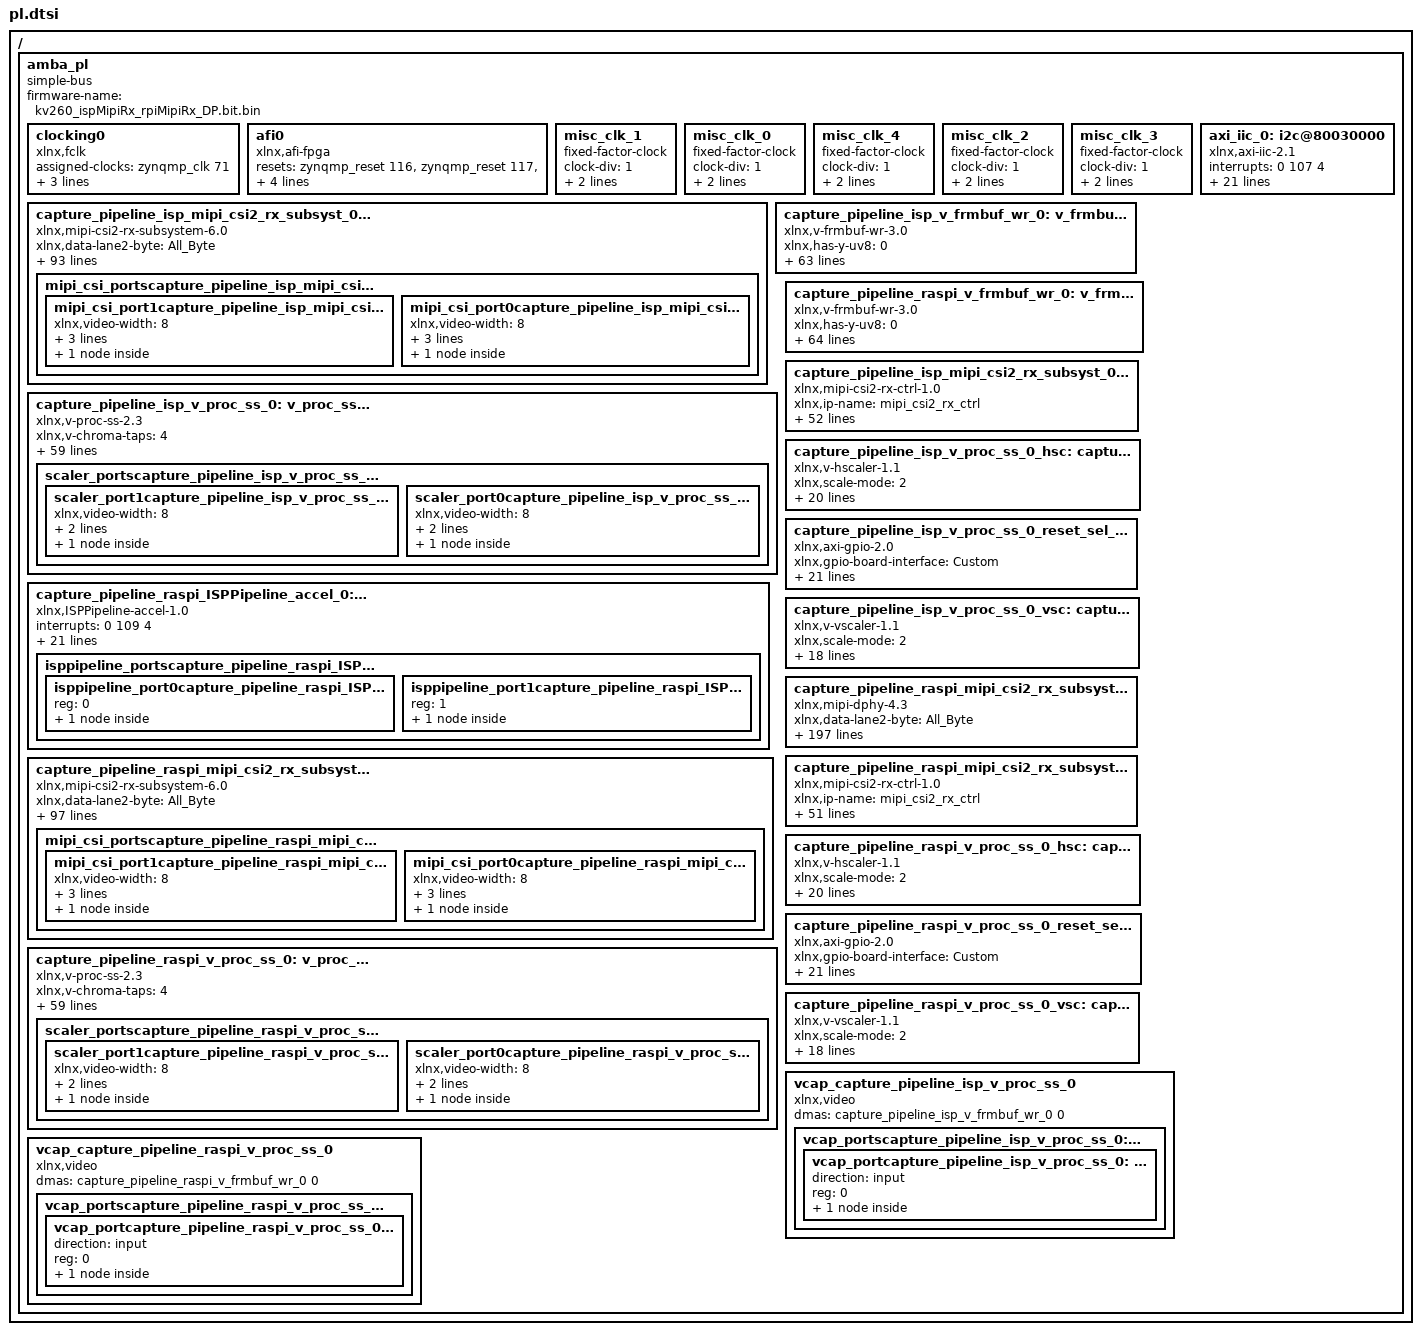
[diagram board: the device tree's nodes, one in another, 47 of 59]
/ {
	amba_pl: amba_pl {
		ranges;
		compatible = "simple-bus";
		#address-cells = <2>;
		#size-cells = <2>;
		firmware-name = "kv260_ispMipiRx_rpiMipiRx_DP.bit.bin";
		clocking0: clocking0 {
			compatible = "xlnx,fclk";
			status = "okay";
			assigned-clocks = <&zynqmp_clk 71>;
			assigned-clock-rates = <99999001>;
			#clock-cells = <0>;
			clock-output-names = "fabric_clk";
			clocks = <&zynqmp_clk 71>;
		};
		afi0: afi0 {
			status = "okay";
			compatible = "xlnx,afi-fpga";
			resets = <&zynqmp_reset 116>, <&zynqmp_reset 117>, <&zynqmp_reset 118>, <&zynqmp_reset 119>;
			config-afi = < 0 0>, <1 0>, <2 0>, <3 0>, <4 1>, <5 1>, <6 0>, <7 0>, <8 1>, <9 1>, <10 0>, <11 0>, <12 0>, <13 0>, <14 0x200>, <15 0x000>;
		};
		misc_clk_1: misc_clk_1 {
			clock-div = <1>;
			compatible = "fixed-factor-clock";
			clock-mult = <2>;
			clocks = <&zynqmp_clk 71>;
			#clock-cells = <0>;
		};
		misc_clk_0: misc_clk_0 {
			clock-div = <1>;
			compatible = "fixed-factor-clock";
			clock-mult = <1>;
			clocks = <&zynqmp_clk 71>;
			#clock-cells = <0>;
		};
		misc_clk_4: misc_clk_4 {
			clock-div = <1>;
			compatible = "fixed-factor-clock";
			clock-mult = <1>;
			clocks = <&zynqmp_clk 71>;
			#clock-cells = <0>;
		};
		misc_clk_2: misc_clk_2 {
			clock-div = <1>;
			compatible = "fixed-factor-clock";
			clock-mult = <15>;
			clocks = <&zynqmp_clk 71>;
			#clock-cells = <0>;
		};
		misc_clk_3: misc_clk_3 {
			clock-div = <1>;
			compatible = "fixed-factor-clock";
			clock-mult = <1>;
			clocks = <&zynqmp_clk 71>;
			#clock-cells = <0>;
		};
		axi_iic_0: i2c@80030000 {
			interrupts = < 0 107 4 >;
			xlnx,iic-freq-khz = <400>;
			compatible = "xlnx,axi-iic-2.1" , "xlnx,xps-iic-2.00.a";
			xlnx,scl-inertial-delay = <0>;
			interrupt-parent = <&imux>;
			xlnx,ip-name = "axi_iic";
			xlnx,disable-setup-violation-check = <0>;
			reg = <0x0 0x80030000 0x0 0x10000>;
			clocks = <&misc_clk_0>;
			xlnx,gpo-width = <1>;
			xlnx,edk-iptype = "PERIPHERAL";
			xlnx,static-timing-reg-width = <0>;
			xlnx,sda-level = <1>;
			status = "okay";
			clock-names = "s_axi_aclk";
			xlnx,ten-bit-adr = <0>;
			xlnx,default-value = <0x0>;
			interrupt-names = "iic2intc_irpt";
			xlnx,iic-board-interface = "som240_1_connector_hda_iic_switch";
			xlnx,timing-reg-width = <32>;
			xlnx,iic-freq = <400000>;
			xlnx,smbus-pmbus-host = <0>;
			xlnx,name = "axi_iic_0";
			xlnx,axi-aclk-freq-mhz = <0x5f5dd18>;
			xlnx,sda-inertial-delay = <0>;
		};
		capture_pipeline_isp_mipi_csi2_rx_subsyst_0: mipi_csi2_rx_subsystem@80000000 {
			xlnx,data-lane2-byte = "All_Byte";
			xlnx,dpy-en-reg-if = <0>;
			xlnx,cmn-vc = <0>;
			xlnx,dphy-lanes = <4>;
			xlnx,ip-name = "mipi_csi2_rx_subsystem";
			reg = <0x0 0x80000000 0x0 0x1000>;
			xlnx,vfb-tu-width = <1>;
			xlnx,ppc = <1>;
			xlnx,csi-buf-depth = <4096>;
			xlnx,exdes-fmc = "LI-IMX274MIPI-FMC , V1.0 , Single , Sensor";
			xlnx,supportlevel = <1>;
			xlnx,clk-lane-io-loc-name = "IO_L1P_T0L_N0_DBC_66";
			xlnx,max-lanes = <4>;
			xlnx,cmn-inc-iic = <0>;
			xlnx,clk-lane-io-loc = "G1";
			xlnx,esc-timeout = <25600>;
			interrupt-names = "csirxss_csi_irq";
			xlnx,cmn-inc-vfb;
			xlnx,axis-tuser-width = <96>;
			compatible = "xlnx,mipi-csi2-rx-subsystem-6.0" , "xlnx,mipi-csi2-rx-subsystem-5.0";
			xlnx,en-active-lanes;
			xlnx,idly-tap = <1>;
			xlnx,cmn-num-pixels = <1>;
			xlnx,cmn-proj-family = <1>;
			xlnx,csi2rx-dbg = <0>;
			xlnx,fifo-rd-en-control;
			xlnx,vfb;
			interrupt-parent = <&imux>;
			xlnx,data-lane1-io-loc-name = "IO_L3P_T0L_N4_AD15P_66";
			xlnx,hs-timeout = <65541>;
			xlnx,data-lane3-io-loc-name = "IO_L5P_T0U_N8_AD14P_66";
			xlnx,ext-mmcm = <0>;
			xlnx,data-lane1-byte = "All_Byte";
			xlnx,cal-mode = "NONE";
			xlnx,csi-filter-userdatatype;
			xlnx,mipi-rx-phy-mode = <1>;
			status = "okay";
			xlnx,data-lane0-io-position = <2>;
			xlnx,exdes-board = "ZCU102";
			xlnx,data-lane2-io-position = <6>;
			xlnx,en-vcx = <0>;
			xlnx,name = "capture_pipeline_isp_mipi_csi2_rx_subsyst_0";
			xlnx,csi-emb-non-img = <0>;
			interrupts = < 0 104 4 >;
			xlnx,dphyrx-board-interface = "som240_1_connector_mipi_csi_isp";
			xlnx,data-lane3-io-loc = "E4";
			xlnx,hs-settle-ns = <146>;
			clocks = <&misc_clk_1>, <&misc_clk_0>, <&misc_clk_1>;
			xlnx,data-lane2-io-loc = "G3";
			xlnx,mipi-slv-int = <0>;
			xlnx,cmn-fifo-rd-en-cntrl;
			xlnx,data-lane3-byte = "All_Byte";
			xlnx,axis-tdest-width = <4>;
			xlnx,phy-mode = "DPHY";
			xlnx,stretch-line-rate = <4500>;
			xlnx,en-csi-v2 = <0>;
			xlnx,edk-iptype = "PERIPHERAL";
			xlnx,init = <100000>;
			xlnx,cmn-pxl-format = <0x18>;
			xlnx,int-qor-check = <0>;
			clock-names = "dphy_clk_200M" , "lite_aclk" , "video_aclk";
			xlnx,data-lane1-io-loc = "F2";
			xlnx,data-lane0-byte = "All_Byte";
			xlnx,ooc-vid-clk = <0x65b710>;
			csirx-present = <1>;
			xlnx,yuv420-buf-dpth = <4096>;
			xlnx,hp-io-bank-selection = <66>;
			xlnx,idly-group-name = "mipi_csi2rx_idly_group";
			xlnx,lprx-disable-extport = <0>;
			csirx-connected = <&capture_pipeline_isp_mipi_csi2_rx_subsyst_0_rx>;
			xlnx,highaddr = <0x80000fff>;
			xlnx,cmn-num-lanes = <4>;
			xlnx,exdes-config = "MIPI_Video_Pipe_Camera_to_Display";
			xlnx,exdesboard-version = <2>;
			xlnx,dphy-preset = "CSI2RX_XLNX";
			xlnx,data-lane0-io-loc-name = "IO_L2P_T0L_N2_66";
			xlnx,csi-pxl-format = <0x18>;
			xlnx,clk-lane-io-position = <0>;
			xlnx,data-lane2-io-loc-name = "IO_L4P_T0U_N6_DBC_AD7P_66";
			xlnx,data-lane0-io-loc = "E1";
			xlnx,inc-phy;
			xlnx,hs-line-rate = <896>;
			xlnx,dpy-line-rate = <896>;
			xlnx,csi-en-crc = <1>;
			xlnx,axis-tdata-width = <32>;
			xlnx,csi-controller-reg-if;
			xlnx,data-lane1-io-position = <4>;
			xlnx,dphy-mode = "SLAVE";
			xlnx,data-lane3-io-position = <8>;
			mipi_csi_portscapture_pipeline_isp_mipi_csi2_rx_subsyst_0: ports {
				#address-cells = <1>;
				#size-cells = <0>;
				mipi_csi_port1capture_pipeline_isp_mipi_csi2_rx_subsyst_0: port@1 {
					xlnx,video-width = <8>;
					reg = <1>;
					xlnx,video-format = <12>;
					xlnx,cfa-pattern = "rggb";
					mipi_csirx_outcapture_pipeline_isp_mipi_csi2_rx_subsyst_0: endpoint {
						remote-endpoint = <&capture_pipeline_isp_v_proc_ss_0capture_pipeline_isp_mipi_csi2_rx_subsyst_0>;
					};
				};
				mipi_csi_port0capture_pipeline_isp_mipi_csi2_rx_subsyst_0: port@0 {
					xlnx,video-width = <8>;
					reg = <0>;
					xlnx,video-format = <12>;
					xlnx,cfa-pattern = "rggb";
					mipi_csi_incapture_pipeline_isp_mipi_csi2_rx_subsyst_0: endpoint {
						data-lanes = < 1 2 3 4 >;
					};
				};
			};
		};
		capture_pipeline_isp_v_frmbuf_wr_0: v_frmbuf_wr@b0010000 {
			xlnx,has-y-uv8 = <0>;
			reset-gpios = <&gpio 78 1>;
			xlnx,max-height = <1080>;
			xlnx,has-bgra8 = <0>;
			xlnx,has-rgba8 = <0>;
			xlnx,ip-name = "v_frmbuf_wr";
			reg = <0x0 0xb0010000 0x0 0x10000>;
			xlnx,s-axi-ctrl-addr-width = <0x7>;
			xlnx,pixels-per-clock = <1>;
			xlnx,samples-per-clock = <1>;
			xlnx,max-nr-planes = <2>;
			xlnx,has-bgr8 = <1>;
			xlnx,has-rgb8 = <1>;
			xlnx,has-y-uv8-420 = <1>;
			xlnx,has-yuyv8 = <0>;
			xlnx,has-y-u-v8 = <0>;
			interrupt-names = "interrupt";
			compatible = "xlnx,v-frmbuf-wr-3.0" , "xlnx,axi-frmbuf-wr-v2.2";
			xlnx,max-width = <1920>;
			xlnx,has-rgb16 = <0>;
			xlnx,vid-formats = "rgb888" , "bgr888" , "nv12";
			xlnx,has-bgrx8 = <0>;
			xlnx,has-rgbx8 = <0>;
			xlnx,has-rgbx10 = <0>;
			interrupt-parent = <&imux>;
			xlnx,aximm-num-outstanding = <4>;
			xlnx,has-uyvy8 = <0>;
			xlnx,use-uram = <0>;
			xlnx,has-rgbx12 = <0>;
			xlnx,aximm-burst-length = <16>;
			xlnx,aximm-addr-width = <32>;
			xlnx,video-width = <8>;
			xlnx,max-cols = <1920>;
			xlnx,has-yuv8 = <0>;
			status = "okay";
			xlnx,has-y-uv10-420 = <0>;
			xlnx,has-yuva8 = <0>;
			xlnx,has-y-uv12-420 = <0>;
			xlnx,name = "capture_pipeline_isp_v_frmbuf_wr_0";
			interrupts = < 0 105 4 >;
			xlnx,has-y10 = <0>;
			xlnx,has-y-uv16-420 = <0>;
			xlnx,has-y12 = <0>;
			xlnx,has-alpha = <0>;
			xlnx,has-y-u-v10 = <0>;
			clocks = <&misc_clk_1>;
			xlnx,has-y16 = <0>;
			xlnx,dma-align = <8>;
			xlnx,has-y-u-v12 = <0>;
			xlnx,edk-iptype = "PERIPHERAL";
			xlnx,has-interlaced = <0>;
			xlnx,has-yuv16 = <0>;
			xlnx,has-yuvx8 = <0>;
			xlnx,is-tile-format = <0>;
			xlnx,dma-addr-width = <32>;
			clock-names = "ap_clk";
			xlnx,s-axi-ctrl-data-width = <0x20>;
			xlnx,has-y8 = <0>;
			xlnx,has-y-uv10 = <0>;
			xlnx,has-y-uv12 = <0>;
			xlnx,max-rows = <1080>;
			xlnx,has-yuvx10 = <0>;
			#dma-cells = <1>;
			xlnx,has-yuvx12 = <0>;
			xlnx,has-y-uv16 = <0>;
			xlnx,max-data-width = <8>;
			xlnx,has-y-u-v8-420 = <0>;
			xlnx,num-video-components = <3>;
			xlnx,aximm-data-width = <64>;
		};
		capture_pipeline_isp_v_proc_ss_0: v_proc_ss@b00c0000 {
			xlnx,v-chroma-taps = <4>;
			xlnx,h-chroma-algorithm = <2>;
			hcrsmplr-present = <0>;
			reset-gpios = <&gpio 85 1>;
			xlnx,max-height = <1080>;
			rstaxis-present = <1>;
			vscale-present = <1>;
			xlnx,ip-name = "v_proc_ss";
			xlnx,enable-interlaced;
			reg = <0x0 0xb00c0000 0x0 0x40000>;
			hscale-present = <1>;
			xlnx,deint-motion-adaptive;
			xlnx,num-hori-taps = <6>;
			xlnx,h-scaler-taps = <6>;
			deint-present = <0>;
			xlnx,topology = <0>;
			xlnx,chroma-algorithm = <2>;
			compatible = "xlnx,v-proc-ss-2.3" , "xlnx,v-vpss-scaler-2.2";
			xlnx,csc-enable-window =  "true";
			xlnx,max-width = <1920>;
			xlnx,aximm-num-outstanding = <16>;
			xlnx,use-uram = <0>;
			rstaxis-connected = <&capture_pipeline_isp_v_proc_ss_0_reset_sel_axis>;
			vscale-connected = <&capture_pipeline_isp_v_proc_ss_0_vsc>;
			xlnx,aximm-burst-length = <16>;
			xlnx,aximm-addr-width = <32>;
			xlnx,v-scaler-taps = <6>;
			xlnx,scaler-enable-422;
			xlnx,video-width = <8>;
			xlnx,max-cols = <1920>;
			xlnx,colorspace-support = <0>;
			status = "okay";
			xlnx,read-fifo-depth = <128>;
			vdma-present = <0>;
			xlnx,name = "capture_pipeline_isp_v_proc_ss_0";
			xlnx,csc-enable-422 =  "true";
			xlnx,num-vert-taps = <6>;
			xlnx,pix-per-clk = <1>;
			xlnx,enable-csc =  "true";
			xlnx,scaler-algorithm = <2>;
			xlnx,v-scaler-phases = <64>;
			clocks = <&misc_clk_1>, <&misc_clk_1>;
			xlnx,max-num-phases = <64>;
			xlnx,edk-iptype = "PERIPHERAL";
			lbox-present = <0>;
			clock-names = "aclk_axis" , "aclk_ctrl";
			router-present = <0>;
			xlnx,highaddr = <0xb00fffff>;
			xlnx,h-chroma-taps = <4>;
			xlnx,max-rows = <1080>;
			xlnx,h-scaler-phases = <64>;
			xlnx,max-data-width = <8>;
			hscale-connected = <&capture_pipeline_isp_v_proc_ss_0_hsc>;
			xlnx,enable-dma;
			xlnx,write-fifo-depth = <128>;
			xlnx,num-video-components = <3>;
			xlnx,aximm-data-width = <64>;
			xlnx,samples-per-clk = <1>;
			xlnx,v-chroma-algorithm = <2>;
			csc-present = <0>;
			scaler_portscapture_pipeline_isp_v_proc_ss_0: ports {
				#address-cells = <1>;
				#size-cells = <0>;
				scaler_port1capture_pipeline_isp_v_proc_ss_0: port@1 {
					xlnx,video-width = <8>;
					reg = <1>;
					xlnx,video-format = <3>;
					sca_outcapture_pipeline_isp_v_proc_ss_0: endpoint {
						remote-endpoint = <&capture_pipeline_isp_v_frmbuf_wr_0capture_pipeline_isp_v_proc_ss_0>;
					};
				};
				scaler_port0capture_pipeline_isp_v_proc_ss_0: port@0 {
					xlnx,video-width = <8>;
					reg = <0>;
					xlnx,video-format = <3>;
					capture_pipeline_isp_v_proc_ss_0capture_pipeline_isp_mipi_csi2_rx_subsyst_0: endpoint {
						remote-endpoint = <&mipi_csirx_outcapture_pipeline_isp_mipi_csi2_rx_subsyst_0>;
					};
				};
			};
		};
		capture_pipeline_raspi_ISPPipeline_accel_0: ISPPipeline_accel@b0000000 {
			interrupts = < 0 109 4 >;
			compatible = "xlnx,ISPPipeline-accel-1.0" , "xlnx,isppipeline-1.0";
			xlnx,ii = "2078101 , ~ , 2111159";
			xlnx,max-width = /bits/ 16 <3840>;
			reset-gpios = <&gpio 82 0>;
			xlnx,max-height = /bits/ 16 <2160>;
			xlnx,machine = <64>;
			interrupt-parent = <&imux>;
			xlnx,ip-name = "ISPPipeline_accel";
			reg = <0x0 0xb0000000 0x0 0x10000>;
			xlnx,bgain = /bits/ 16 <210>;
			xlnx,rgain = /bits/ 16 <128>;
			clocks = <&misc_clk_1>;
			xlnx,s-axi-ctrl-addr-width = <15>;
			xlnx,pawb = /bits/ 16 <350>;
			xlnx,clk-period = <0x325aa0>;
			xlnx,edk-iptype = "PERIPHERAL";
			status = "okay";
			clock-names = "ap_clk";
			xlnx,mode-reg;
			interrupt-names = "interrupt";
			xlnx,combinational = <0>;
			xlnx,s-axi-ctrl-data-width = <32>;
			xlnx,latency = <2078100>;
			xlnx,name = "capture_pipeline_raspi_ISPPipeline_accel_0";
			isppipeline_portscapture_pipeline_raspi_ISPPipeline_accel_0: ports {
				#address-cells = <1>;
				#size-cells = <0>;
				isppipeline_port0capture_pipeline_raspi_ISPPipeline_accel_0: port@0 {
					reg = <0>;
					capture_pipeline_raspi_ISPPipeline_accel_0capture_pipeline_raspi_mipi_csi2_rx_subsyst_0: endpoint {
						remote-endpoint = <&isppipeline_incapture_pipeline_raspi_ISPPipeline_accel_0>;
					};
				};
				isppipeline_port1capture_pipeline_raspi_ISPPipeline_accel_0: port@1 {
					reg = <1>;
					capture_pipeline_raspi_ISPPipeline_accel_0capture_pipeline_raspi_v_proc_ss_0: endpoint {
						remote-endpoint = <&v_proc_sscapture_pipeline_raspi_ISPPipeline_accel_0>;
					};
				};
			};
		};
		capture_pipeline_raspi_mipi_csi2_rx_subsyst_0: mipi_csi2_rx_subsystem@80002000 {
			xlnx,data-lane2-byte = "All_Byte";
			xlnx,dpy-en-reg-if = <1>;
			xlnx,cmn-vc = <4>;
			xlnx,dphy-lanes = <2>;
			xlnx,ip-name = "mipi_csi2_rx_subsystem";
			reg = <0x0 0x80002000 0x0 0x2000>;
			xlnx,vfb-tu-width = <1>;
			xlnx,ppc = <1>;
			xlnx,csi-buf-depth = <512>;
			xlnx,exdes-fmc = "LI-IMX274MIPI-FMC , V1.0 , Single , Sensor";
			xlnx,supportlevel = <0>;
			xlnx,clk-lane-io-loc-name = "IO_L13P_T2L_N0_GC_QBC_66";
			xlnx,max-lanes = <2>;
			xlnx,cmn-inc-iic = <0>;
			xlnx,clk-lane-io-loc = "D7";
			xlnx,esc-timeout = <25600>;
			interrupt-names = "csirxss_csi_irq";
			xlnx,cmn-inc-vfb;
			xlnx,axis-tuser-width = <96>;
			compatible = "xlnx,mipi-csi2-rx-subsystem-6.0" , "xlnx,mipi-csi2-rx-subsystem-5.0";
			xlnx,en-active-lanes;
			xlnx,idly-tap = <1>;
			dphy-present = <1>;
			xlnx,cmn-num-pixels = <1>;
			xlnx,cmn-proj-family = <1>;
			xlnx,csi2rx-dbg = <0>;
			xlnx,fifo-rd-en-control;
			xlnx,vfb;
			interrupt-parent = <&imux>;
			xlnx,data-lane1-io-loc-name = "IO_L15P_T2L_N4_AD11P_66";
			dphy-connected = <&capture_pipeline_raspi_mipi_csi2_rx_subsyst_0_phy>;
			xlnx,hs-timeout = <65541>;
			xlnx,data-lane3-io-loc-name = "None";
			xlnx,ext-mmcm = <0>;
			xlnx,data-lane1-byte = "All_Byte";
			xlnx,cal-mode = "NONE";
			xlnx,mipi-rx-phy-mode = <1>;
			status = "okay";
			xlnx,data-lane0-io-position = <28>;
			xlnx,exdes-board = "ZCU102";
			xlnx,data-lane2-io-position = <19>;
			xlnx,vc = <4>;
			xlnx,en-vcx = <0>;
			xlnx,name = "capture_pipeline_raspi_mipi_csi2_rx_subsyst_0";
			xlnx,csi-emb-non-img = <0>;
			interrupts = < 0 108 4 >;
			xlnx,dphyrx-board-interface = "som240_1_connector_mipi_csi_raspi";
			xlnx,data-lane3-io-loc = "None";
			xlnx,hs-settle-ns = <145>;
			clocks = <&misc_clk_2>, <&misc_clk_1>, <&misc_clk_0>, <&misc_clk_1>;
			xlnx,data-lane2-io-loc = "None";
			xlnx,mipi-slv-int = <0>;
			xlnx,cmn-fifo-rd-en-cntrl;
			xlnx,data-lane3-byte = "All_Byte";
			xlnx,axis-tdest-width = <4>;
			xlnx,phy-mode = "DPHY";
			xlnx,stretch-line-rate = <1500>;
			xlnx,en-csi-v2 = <0>;
			xlnx,edk-iptype = "PERIPHERAL";
			xlnx,init = <100000>;
			xlnx,cmn-pxl-format = <0x2b>;
			xlnx,int-qor-check = <0>;
			clock-names = "clkoutphy_in" , "dphy_clk_200M" , "lite_aclk" , "video_aclk";
			xlnx,data-lane1-io-loc = "G6";
			xlnx,data-lane0-byte = "All_Byte";
			xlnx,ooc-vid-clk = <0x65b710>;
			csirx-present = <1>;
			xlnx,yuv420-buf-dpth = <128>;
			xlnx,hp-io-bank-selection = <66>;
			xlnx,idly-group-name = "mipi_csi2rx_idly_group";
			xlnx,lprx-disable-extport = <0>;
			csirx-connected = <&capture_pipeline_raspi_mipi_csi2_rx_subsyst_0_rx>;
			xlnx,highaddr = <0x80003fff>;
			xlnx,cmn-num-lanes = <2>;
			xlnx,exdes-config = "MIPI_Video_Pipe_Camera_to_Display";
			xlnx,exdesboard-version = <2>;
			xlnx,dphy-preset = "CSI2RX_XLNX";
			xlnx,data-lane0-io-loc-name = "IO_L14P_T2L_N2_GC_66";
			xlnx,csi-pxl-format = <0x2b>;
			xlnx,clk-lane-io-position = <26>;
			xlnx,data-lane2-io-loc-name = "None";
			xlnx,data-lane0-io-loc = "E5";
			xlnx,inc-phy;
			xlnx,hs-line-rate = <912>;
			rxphy-present = <0>;
			xlnx,dpy-line-rate = <912>;
			xlnx,csi-en-crc = <0>;
			xlnx,axis-tdata-width = <32>;
			xlnx,data-lane1-io-position = <30>;
			xlnx,dphy-mode = "SLAVE";
			xlnx,csi-controller-reg-if;
			xlnx,data-lane3-io-position = <21>;
			mipi_csi_portscapture_pipeline_raspi_mipi_csi2_rx_subsyst_0: ports {
				#address-cells = <1>;
				#size-cells = <0>;
				mipi_csi_port1capture_pipeline_raspi_mipi_csi2_rx_subsyst_0: port@1 {
					xlnx,video-width = <8>;
					reg = <1>;
					xlnx,video-format = <12>;
					xlnx,cfa-pattern = "rggb";
					mipi_csirx_outcapture_pipeline_raspi_mipi_csi2_rx_subsyst_0: endpoint {
						remote-endpoint = <&capture_pipeline_raspi_ISPPipeline_accel_0capture_pipeline_raspi_mipi_csi2_rx_subsyst_0>;
					};
				};
				mipi_csi_port0capture_pipeline_raspi_mipi_csi2_rx_subsyst_0: port@0 {
					xlnx,video-width = <8>;
					reg = <0>;
					xlnx,video-format = <12>;
					xlnx,cfa-pattern = "rggb";
					mipi_csi_incapture_pipeline_raspi_mipi_csi2_rx_subsyst_0: endpoint {
						data-lanes = < 1 2 >;
					};
				};
			};
		};
		capture_pipeline_raspi_v_frmbuf_wr_0: v_frmbuf_wr@b0080000 {
			xlnx,has-y-uv8 = <0>;
			reset-gpios = <&gpio 84 1>;
			xlnx,max-height = <1080>;
			xlnx,has-bgra8 = <0>;
			xlnx,has-rgba8 = <0>;
			xlnx,ip-name = "v_frmbuf_wr";
			reg = <0x0 0xb0080000 0x0 0x10000>;
			xlnx,s-axi-ctrl-addr-width = <0x7>;
			xlnx,pixels-per-clock = <1>;
			xlnx,samples-per-clock = <1>;
			xlnx,max-nr-planes = <2>;
			xlnx,has-bgr8 = <1>;
			xlnx,has-rgb8 = <1>;
			xlnx,has-y-uv8-420 = <1>;
			xlnx,has-yuyv8 = <0>;
			xlnx,has-y-u-v8 = <0>;
			interrupt-names = "interrupt";
			compatible = "xlnx,v-frmbuf-wr-3.0" , "xlnx,axi-frmbuf-wr-v2.2";
			xlnx,max-width = <1920>;
			xlnx,has-rgb16 = <0>;
			xlnx,vid-formats = "rgb888" , "bgr888" , "nv12";
			xlnx,has-bgrx8 = <0>;
			xlnx,has-rgbx8 = <0>;
			xlnx,has-rgbx10 = <0>;
			interrupt-parent = <&imux>;
			xlnx,aximm-num-outstanding = <4>;
			xlnx,has-uyvy8 = <0>;
			xlnx,use-uram = <0>;
			xlnx,has-rgbx12 = <0>;
			xlnx,aximm-burst-length = <16>;
			xlnx,aximm-addr-width = <32>;
			xlnx,video-width = <8>;
			xlnx,max-cols = <1920>;
			xlnx,has-yuv8 = <0>;
			status = "okay";
			xlnx,has-y-uv10-420 = <0>;
			xlnx,has-yuva8 = <0>;
			xlnx,has-y-uv12-420 = <0>;
			xlnx,name = "capture_pipeline_raspi_v_frmbuf_wr_0";
			interrupts = < 0 106 4 >;
			xlnx,has-y10 = <0>;
			xlnx,has-y-uv16-420 = <0>;
			xlnx,has-y12 = <0>;
			xlnx,has-alpha = <0>;
			xlnx,has-y-u-v10 = <0>;
			clocks = <&misc_clk_1>;
			xlnx,has-y16 = <0>;
			xlnx,dma-align = <8>;
			xlnx,has-y-u-v12 = <0>;
			xlnx,edk-iptype = "PERIPHERAL";
			xlnx,has-interlaced = <0>;
			xlnx,has-yuv16 = <0>;
			xlnx,has-yuvx8 = <0>;
			xlnx,is-tile-format = <0>;
			xlnx,dma-addr-width = <32>;
			clock-names = "ap_clk";
			xlnx,s-axi-ctrl-data-width = <0x20>;
			xlnx,has-y8 = <0>;
			xlnx,has-y-uv10 = <0>;
			xlnx,has-y-uv12 = <0>;
			xlnx,max-rows = <1080>;
			xlnx,has-yuvx10 = <0>;
			#dma-cells = <1>;
			xlnx,has-yuvx12 = <0>;
			xlnx,has-y-uv16 = <0>;
			xlnx,max-data-width = <8>;
			xlnx,has-y-u-v8-420 = <0>;
			xlnx,num-video-components = <3>;
			xlnx,aximm-data-width = <64>;
		};
		capture_pipeline_raspi_v_proc_ss_0: v_proc_ss@b0040000 {
			xlnx,v-chroma-taps = <4>;
			xlnx,h-chroma-algorithm = <2>;
			hcrsmplr-present = <0>;
			reset-gpios = <&gpio 83 1>;
			xlnx,max-height = <1080>;
			rstaxis-present = <1>;
			vscale-present = <1>;
			xlnx,ip-name = "v_proc_ss";
			xlnx,enable-interlaced;
			reg = <0x0 0xb0040000 0x0 0x40000>;
			hscale-present = <1>;
			xlnx,deint-motion-adaptive;
			xlnx,num-hori-taps = <6>;
			xlnx,h-scaler-taps = <6>;
			deint-present = <0>;
			xlnx,topology = <0>;
			xlnx,chroma-algorithm = <2>;
			compatible = "xlnx,v-proc-ss-2.3" , "xlnx,v-vpss-scaler-2.2";
			xlnx,csc-enable-window =  "true";
			xlnx,max-width = <1920>;
			xlnx,aximm-num-outstanding = <16>;
			xlnx,use-uram = <0>;
			rstaxis-connected = <&capture_pipeline_raspi_v_proc_ss_0_reset_sel_axis>;
			vscale-connected = <&capture_pipeline_raspi_v_proc_ss_0_vsc>;
			xlnx,aximm-burst-length = <16>;
			xlnx,aximm-addr-width = <32>;
			xlnx,v-scaler-taps = <6>;
			xlnx,scaler-enable-422;
			xlnx,video-width = <8>;
			xlnx,max-cols = <1920>;
			xlnx,colorspace-support = <0>;
			status = "okay";
			xlnx,read-fifo-depth = <128>;
			vdma-present = <0>;
			xlnx,name = "capture_pipeline_raspi_v_proc_ss_0";
			xlnx,csc-enable-422 =  "true";
			xlnx,num-vert-taps = <6>;
			xlnx,pix-per-clk = <1>;
			xlnx,enable-csc =  "true";
			xlnx,scaler-algorithm = <2>;
			xlnx,v-scaler-phases = <64>;
			clocks = <&misc_clk_1>, <&misc_clk_1>;
			xlnx,max-num-phases = <64>;
			xlnx,edk-iptype = "PERIPHERAL";
			lbox-present = <0>;
			clock-names = "aclk_axis" , "aclk_ctrl";
			router-present = <0>;
			xlnx,highaddr = <0xb007ffff>;
			xlnx,h-chroma-taps = <4>;
			xlnx,max-rows = <1080>;
			xlnx,h-scaler-phases = <64>;
			xlnx,max-data-width = <8>;
			hscale-connected = <&capture_pipeline_raspi_v_proc_ss_0_hsc>;
			xlnx,enable-dma;
			xlnx,write-fifo-depth = <128>;
			xlnx,num-video-components = <3>;
			xlnx,aximm-data-width = <64>;
			xlnx,samples-per-clk = <1>;
			xlnx,v-chroma-algorithm = <2>;
			csc-present = <0>;
			scaler_portscapture_pipeline_raspi_v_proc_ss_0: ports {
				#address-cells = <1>;
				#size-cells = <0>;
				scaler_port1capture_pipeline_raspi_v_proc_ss_0: port@1 {
					xlnx,video-width = <8>;
					reg = <1>;
					xlnx,video-format = <3>;
					sca_outcapture_pipeline_raspi_v_proc_ss_0: endpoint {
						remote-endpoint = <&capture_pipeline_raspi_v_frmbuf_wr_0capture_pipeline_raspi_v_proc_ss_0>;
					};
				};
				scaler_port0capture_pipeline_raspi_v_proc_ss_0: port@0 {
					xlnx,video-width = <8>;
					reg = <0>;
					xlnx,video-format = <3>;
					v_proc_sscapture_pipeline_raspi_ISPPipeline_accel_0: endpoint {
						remote-endpoint = <&capture_pipeline_raspi_ISPPipeline_accel_0capture_pipeline_raspi_v_proc_ss_0>;
					};
				};
			};
		};
		capture_pipeline_isp_mipi_csi2_rx_subsyst_0_rx: capture_pipeline_isp_mipi_csi2_rx_subsyst_0_rx@0 {
			xlnx,ip-name = "mipi_csi2_rx_ctrl";
			reg = <0x0 0x00000000 0x0 0x1000>;
			xlnx,ppi-sig-width = <0>;
			xlnx,cmn-inc-vfb = <0>;
			xlnx,axis-tuser-width = <96>;
			compatible = "xlnx,mipi-csi2-rx-ctrl-1.0";
			xlnx,cmn-num-pixels = <1>;
			xlnx,cmn-proj-family = <0>;
			xlnx,csi2rx-dbg = <0>;
			xlnx,csi-opt1-regs = <0>;
			xlnx,disable-lite = <0>;
			xlnx,ppi-sync-width = <0>;
			xlnx,csi-filter-userdatatype = <1>;
			xlnx,csi-offload-nonimage = <0>;
			xlnx,csi-vc-off-10 = <11>;
			xlnx,emb-dw = <64>;
			xlnx,csi-vc-off-11 = <12>;
			xlnx,csi-vc-off-12 = <13>;
			status = "okay";
			xlnx,csi-vc-off-13 = <14>;
			xlnx,csi-vc-off-14 = <15>;
			xlnx,ppi-mult = <0>;
			xlnx,name = "capture_pipeline_isp_mipi_csi2_rx_subsyst_0_rx";
			xlnx,csi-vc-off-0 = <1>;
			xlnx,csi-vc-off-1 = <2>;
			xlnx,csi-vc-off-2 = <3>;
			xlnx,csi-vc-off-3 = <4>;
			xlnx,csi-vc-off-4 = <5>;
			xlnx,csi-lanes = <4>;
			xlnx,csi-vc-off-5 = <6>;
			xlnx,is-hierarchy;
			xlnx,axis-fifo-depth = <4096>;
			xlnx,csi-vc-off-6 = <7>;
			clocks = <&misc_clk_1>, <&misc_clk_3>, <&misc_clk_3>, <&misc_clk_3>, <&misc_clk_3>, <&misc_clk_1>, <&misc_clk_0>, <&misc_clk_1>;
			xlnx,axis-fifo-dcnt-width = <12>;
			xlnx,mipi-slv-int = <0>;
			xlnx,csi-vc-off-7 = <8>;
			xlnx,csi-vc-off-8 = <9>;
			xlnx,axis-tdest-width = <4>;
			xlnx,phy-mode = "DPHY";
			xlnx,csi-vc-off-9 = <10>;
			xlnx,edk-iptype = "PERIPHERAL";
			xlnx,cmn-pxl-format = "YUV422_8bit";
			xlnx,csi-opt2-crc = <0>;
			clock-names = "core_clk" , "dl0_rxbyteclkhs" , "dl1_rxbyteclkhs" , "dl2_rxbyteclkhs" , "dl3_rxbyteclkhs" , "m_axis_aclk" , "s_axi_aclk" , "video_aclk";
			xlnx,hp-io-bank-selection = <66>;
			xlnx,csi-opt3-fixedlanes = <1>;
			xlnx,csi-en-vc-support = <0>;
			xlnx,hs-line-rate = <896>;
			xlnx,csi-fixed-vc = <0>;
			xlnx,csi-inv-shutdown = <1>;
			xlnx,axis-tdata-width = <64>;
			xlnx,header-data-width = <32>;
		};
		capture_pipeline_isp_v_proc_ss_0_hsc: capture_pipeline_isp_v_proc_ss_0_hsc@0 {
			xlnx,scale-mode = <2>;
			compatible = "xlnx,v-hscaler-1.1";
			xlnx,phase-shift = <6>;
			xlnx,enable-csc = <1>;
			xlnx,max-rows = <1080>;
			xlnx,use-uram = <0>;
			xlnx,ip-name = "v_hscaler";
			xlnx,is-hierarchy;
			reg = <0x0 0x00000000 0x0 0x10000>;
			clocks = <&misc_clk_1>;
			xlnx,s-axi-ctrl-addr-width = <16>;
			xlnx,samples-per-clock = <1>;
			xlnx,max-data-width = <8>;
			xlnx,enable-420 = <1>;
			xlnx,edk-iptype = "PERIPHERAL";
			xlnx,enable-422 = <1>;
			xlnx,max-cols = <1920>;
			status = "okay";
			clock-names = "ap_clk";
			xlnx,num-video-components = <3>;
			xlnx,taps = <6>;
			xlnx,s-axi-ctrl-data-width = <32>;
			xlnx,name = "capture_pipeline_isp_v_proc_ss_0_hsc";
		};
		capture_pipeline_isp_v_proc_ss_0_reset_sel_axis: capture_pipeline_isp_v_proc_ss_0_reset_sel_axis@10000 {
			xlnx,gpio-board-interface = "Custom";
			compatible = "xlnx,axi-gpio-2.0" , "xlnx,xps-gpio-1.00.a";
			xlnx,all-outputs = <0>;
			#gpio-cells = <2>;
			xlnx,gpio-width = <2>;
			xlnx,dout-default = <0x0>;
			xlnx,is-dual = <0>;
			xlnx,ip-name = "axi_gpio";
			xlnx,is-hierarchy;
			xlnx,tri-default-2 = <0xffffffff>;
			reg = <0x0 0x00010000 0x0 0x10000>;
			xlnx,all-inputs-2 = <0>;
			clocks = <&misc_clk_1>;
			xlnx,all-outputs-2 = <0>;
			gpio-controller;
			xlnx,interrupt-present = <0>;
			xlnx,gpio2-board-interface = "Custom";
			xlnx,edk-iptype = "PERIPHERAL";
			xlnx,dout-default-2 = <0x0>;
			status = "okay";
			xlnx,gpio2-width = <32>;
			clock-names = "s_axi_aclk";
			xlnx,tri-default = <0xffffffff>;
			xlnx,name = "capture_pipeline_isp_v_proc_ss_0_reset_sel_axis";
			xlnx,all-inputs = <0>;
		};
		capture_pipeline_isp_v_proc_ss_0_vsc: capture_pipeline_isp_v_proc_ss_0_vsc@20000 {
			xlnx,scale-mode = <2>;
			compatible = "xlnx,v-vscaler-1.1";
			xlnx,phase-shift = <6>;
			xlnx,max-rows = <1080>;
			xlnx,use-uram = <0>;
			xlnx,ip-name = "v_vscaler";
			xlnx,is-hierarchy;
			reg = <0x0 0x00020000 0x0 0x10000>;
			clocks = <&misc_clk_1>;
			xlnx,s-axi-ctrl-addr-width = <12>;
			xlnx,samples-per-clock = <1>;
			xlnx,enable-420 = <1>;
			xlnx,max-data-width = <8>;
			xlnx,edk-iptype = "PERIPHERAL";
			xlnx,max-cols = <1920>;
			status = "okay";
			clock-names = "ap_clk";
			xlnx,num-video-components = <3>;
			xlnx,taps = <6>;
			xlnx,s-axi-ctrl-data-width = <32>;
			xlnx,name = "capture_pipeline_isp_v_proc_ss_0_vsc";
		};
		capture_pipeline_raspi_mipi_csi2_rx_subsyst_0_phy: capture_pipeline_raspi_mipi_csi2_rx_subsyst_0_phy@1000 {
			xlnx,data-lane2-byte = "All_Byte";
			xlnx,en-dphy-io = <1>;
			xlnx,skewcal-first-time = <4096>;
			xlnx,clk-lane-txif4-io-loc = "AC9";
			xlnx,data-lane1-txif4-io-position = <4>;
			xlnx,data-lane5-io-position = <51>;
			xlnx,hp-io-bank-name = "66_(HP)_(Half , Bank)";
			xlnx,data-lane2-txif3-io-loc = "AD7";
			xlnx,data-lane2-txif2-byte = "All_Byte";
			xlnx,lpx-period = <50>;
			xlnx,en-tx-algo = <0>;
			xlnx,data-lane3-txif3-io-position = <51>;
			xlnx,en-txcalib-sim = <0>;
			xlnx,dphy-lanes = <2>;
			xlnx,data-lane7-io-position = <51>;
			xlnx,data-lane7-io-loc = "None";
			xlnx,data-lane3-txif3-byte = "All_Byte";
			xlnx,data-lane0-txif2-io-loc-name = "IO_L2P_T0L_N2_64";
			xlnx,ip-name = "mipi_dphy";
			xlnx,txif1-instname = "tx66";
			reg = <0x0 0x00001000 0x0 0x1000>;
			xlnx,clk-lane-txif2-io-position = <0>;
			xlnx,data-lane0-txif4-io-loc-name = "IO_L2P_T0L_N2_64";
			xlnx,en-io-sel = <1>;
			xlnx,en-dcts-logic = <0>;
			xlnx,data-lane2-txif3-io-loc-name = "IO_L4P_T0U_N6_DBC_AD7P_64";
			xlnx,clk-lane-txif3-io-loc = "AC9";
			xlnx,clk-lane-txif4-io-position = <0>;
			xlnx,data-lane2-txif2-io-loc = "AD7";
			xlnx,en-ext-tap = <0>;
			xlnx,pll-divclk-divide = <1>;
			xlnx,data-lane6-io-loc = "None";
			xlnx,tx-output-impedance;
			xlnx,rx-equalization = "EQ_LEVEL4";
			xlnx,clk-lane-io-loc-name = "IO_L13P_T2L_N0_GC_QBC_66";
			xlnx,data-lane7-byte = "All_Byte";
			xlnx,esc-timeout = <25600>;
			xlnx,clk-lane-io-loc = "D7";
			xlnx,en-debug-tx-calib = <0>;
			xlnx,txif2-instname = "tx64";
			xlnx,clk-lane-txif2-io-loc = "AC9";
			xlnx,data-lane0-txif3-io-position = <2>;
			xlnx,ddr-clk-period = <0x217280>;
			xlnx,data-lane0-txif2-byte = "All_Byte";
			xlnx,txpll-clkin-period = <0x85d9a0>;
			xlnx,en-reg-if = <1>;
			compatible = "xlnx,mipi-dphy-4.3";
			xlnx,data-lane2-txif2-io-position = <51>;
			xlnx,txif2-hp-io-bank-selection = <64>;
			xlnx,en-rxppi-as-mon = <0>;
			xlnx,data-lane5-io-loc = "None";
			xlnx,data-lane4-byte = "All_Byte";
			xlnx,data-lane1-txif4-io-loc = "AB8";
			xlnx,data-lane1-txif3-byte = "All_Byte";
			xlnx,idly-tap = <0>;
			xlnx,data-lane2-txif4-io-position = <51>;
			xlnx,fifo-rd-en-control;
			xlnx,dl0-io-swap = <0>;
			xlnx,txif2-hp-io-bank-name = "64_(HP)";
			xlnx,data-lane2-txif4-byte = "All_Byte";
			xlnx,data-lane1-io-loc-name = "IO_L15P_T2L_N4_AD11P_66";
			xlnx,example-simulation = <1>;
			xlnx,dl1-io-swap = <0>;
			xlnx,txif3-hp-io-bank-name = "64_(HP)";
			xlnx,mtbf-sync-stages = <3>;
			xlnx,hs-timeout = <65541>;
			xlnx,dl2-io-swap = <0>;
			xlnx,txif4-hp-io-bank-name = "64_(HP)";
			xlnx,data-lane3-io-loc-name = "None";
			xlnx,data-lane1-txif2-io-loc-name = "IO_L3P_T0L_N4_AD15P_64";
			xlnx,dl3-io-swap = <0>;
			xlnx,data-lane1-byte = "All_Byte";
			xlnx,dl4-io-swap = <0>;
			xlnx,data-lane5-io-loc-name = "None";
			xlnx,data-lane1-txif4-io-loc-name = "IO_L3P_T0L_N4_AD15P_64";
			xlnx,txif3-instname = "tx64";
			xlnx,pll-clk1-divide = <8>;
			xlnx,cal-mode = "FIXED";
			xlnx,dl5-io-swap = <0>;
			xlnx,data-lane4-io-loc = "None";
			xlnx,data-lane3-txif3-io-loc-name = "IO_L5P_T0U_N8_AD14P_64";
			xlnx,data-lane1-txif3-io-loc = "AB8";
			xlnx,use-lane0-txreadyhs;
			xlnx,dl6-io-swap = <0>;
			xlnx,data-lane7-io-loc-name = "None";
			xlnx,dl7-io-swap = <0>;
			xlnx,data-lane3-txif2-byte = "All_Byte";
			xlnx,wakeup = <1000000>;
			xlnx,versal = <0>;
			status = "okay";
			xlnx,data-lane0-io-position = <28>;
			xlnx,en-txsplt = <0>;
			xlnx,clk-lane-txif2-io-loc-name = "IO_L1P_T0L_N0_DBC_64";
			xlnx,data-lane2-io-position = <51>;
			xlnx,pll-clk0-divide = <8>;
			xlnx,name = "capture_pipeline_raspi_mipi_csi2_rx_subsyst_0_phy";
			xlnx,clk-lane-txif4-io-loc-name = "IO_L1P_T0L_N0_DBC_64";
			xlnx,dphyrx-board-interface = "som240_1_connector_mipi_csi_raspi";
			xlnx,data-lane3-io-loc = "None";
			xlnx,data-lane1-txif2-io-loc = "AB8";
			xlnx,data-lane1-txif3-io-position = <4>;
			xlnx,data-lane4-io-position = <51>;
			xlnx,txif4-instname = "tx64";
			xlnx,txif1-createinst;
			xlnx,data-lane3-txif2-io-position = <51>;
			xlnx,data-lane0-txif4-byte = "All_Byte";
			xlnx,data-lane6-io-position = <51>;
			xlnx,txif4-hp-io-bank-selection = <64>;
			xlnx,data-lane3-txif4-io-position = <51>;
			xlnx,data-lane6-byte = "All_Byte";
			xlnx,data-lane3-txif4-io-loc = "AB7";
			xlnx,hs-settle-ns = <145>;
			xlnx,is-hierarchy;
			xlnx,data-lane0-txif3-io-loc-name = "IO_L2P_T0L_N2_64";
			clocks = <&misc_clk_2>, <&misc_clk_1>, <&misc_clk_0>;
			xlnx,xiphy-line-rate-min = <600>;
			xlnx,data-lane2-txif2-io-loc-name = "IO_L4P_T0U_N6_DBC_AD7P_64";
			xlnx,data-lane2-io-loc = "None";
			xlnx,en-ssc = <0>;
			xlnx,clk-lane-txif3-io-position = <0>;
			xlnx,stable-clk-period = <5>;
			xlnx,en-clk300m = <0>;
			xlnx,data-lane3-byte = "All_Byte";
			xlnx,data-lane2-txif4-io-loc-name = "IO_L4P_T0U_N6_DBC_AD7P_64";
			xlnx,data-lane1-txif2-byte = "All_Byte";
			xlnx,data-lane0-txif4-io-loc = "AE9";
			xlnx,stretch-line-rate = <1500>;
			xlnx,edk-iptype = "PERIPHERAL";
			xlnx,init = <100000>;
			xlnx,data-lane3-txif3-io-loc = "AB7";
			xlnx,data-lane2-txif3-byte = "All_Byte";
			clock-names = "clkoutphy_in" , "core_clk" , "s_axi_aclk";
			xlnx,data-lane3-txif4-byte = "All_Byte";
			xlnx,en-hs-obuftds = <0>;
			xlnx,data-lane1-io-loc = "G6";
			xlnx,data-lane0-byte = "All_Byte";
			xlnx,data-lane0-txif2-io-position = <2>;
			xlnx,hp-io-bank-selection = <66>;
			xlnx,pll-divclk-mult = <8>;
			xlnx,data-lane0-txif3-io-loc = "AE9";
			xlnx,lprx-disable-extport = <0>;
			xlnx,idly-group-name = "mipi_csi2rx_idly_group";
			xlnx,esc-clk-period = <50>;
			xlnx,data-lane0-txif4-io-position = <2>;
			xlnx,highaddr = <0x1fff>;
			xlnx,data-lane2-txif3-io-position = <51>;
			xlnx,dphytx-board-interface = "Custom";
			xlnx,data-lane3-txif2-io-loc = "AB7";
			xlnx,dphy-preset = "CSI2RX_XLNX";
			xlnx,data-lane0-io-loc-name = "IO_L14P_T2L_N2_GC_66";
			xlnx,en-timeout-regs = <0>;
			xlnx,clk-lane-io-position = <26>;
			xlnx,div4-clk-period = <0x85d9a0>;
			xlnx,data-lane2-io-loc-name = "None";
			xlnx,data-lane0-io-loc = "E5";
			xlnx,data-lane4-io-loc-name = "None";
			xlnx,data-lane1-txif3-io-loc-name = "IO_L3P_T0L_N4_AD15P_64";
			xlnx,data-lane0-txif2-io-loc = "AE9";
			xlnx,hs-line-rate = <912>;
			xlnx,data-lane3-txif2-io-loc-name = "IO_L5P_T0U_N8_AD14P_64";
			xlnx,skewcal-periodic-time = <128>;
			xlnx,pll-clkoutphy-mode = "VCO";
			xlnx,data-lane6-io-loc-name = "None";
			xlnx,data-lane0-txif3-byte = "All_Byte";
			xlnx,s50-logic = <0>;
			xlnx,txif3-hp-io-bank-selection = <64>;
			xlnx,data-lane3-txif4-io-loc-name = "IO_L5P_T0U_N8_AD14P_64";
			xlnx,tx-riu-wr-gap = <18>;
			xlnx,data-lane5-byte = "All_Byte";
			xlnx,data-lane2-txif4-io-loc = "AD7";
			xlnx,data-lane1-txif4-byte = "All_Byte";
			xlnx,en-debug-regs = <0>;
			xlnx,dphy-mode = <0>;
			xlnx,clk-io-swap = <0>;
			xlnx,data-lane1-io-position = <30>;
			xlnx,en-bufg-on-wr-clk-out;
			xlnx,en-act-lanes = <0>;
			xlnx,dphy-txifs = <1>;
			xlnx,clk-lane-txif3-io-loc-name = "IO_L1P_T0L_N0_DBC_64";
			xlnx,data-lane1-txif2-io-position = <4>;
			xlnx,data-lane3-io-position = <51>;
		};
		capture_pipeline_raspi_mipi_csi2_rx_subsyst_0_rx: capture_pipeline_raspi_mipi_csi2_rx_subsyst_0_rx@0 {
			xlnx,ip-name = "mipi_csi2_rx_ctrl";
			reg = <0x0 0x00000000 0x0 0x1000>;
			xlnx,ppi-sig-width = <0>;
			xlnx,cmn-inc-vfb = <0>;
			xlnx,axis-tuser-width = <96>;
			compatible = "xlnx,mipi-csi2-rx-ctrl-1.0";
			xlnx,cmn-num-pixels = <1>;
			xlnx,cmn-proj-family = <0>;
			xlnx,csi2rx-dbg = <0>;
			xlnx,csi-opt1-regs = <0>;
			xlnx,disable-lite = <0>;
			xlnx,ppi-sync-width = <0>;
			xlnx,csi-filter-userdatatype = <0>;
			xlnx,csi-offload-nonimage = <0>;
			xlnx,csi-vc-off-10 = <11>;
			xlnx,emb-dw = <64>;
			xlnx,csi-vc-off-11 = <12>;
			xlnx,csi-vc-off-12 = <13>;
			status = "okay";
			xlnx,csi-vc-off-13 = <14>;
			xlnx,csi-vc-off-14 = <15>;
			xlnx,ppi-mult = <0>;
			xlnx,name = "capture_pipeline_raspi_mipi_csi2_rx_subsyst_0_rx";
			xlnx,csi-vc-off-0 = <1>;
			xlnx,csi-vc-off-1 = <2>;
			xlnx,csi-vc-off-2 = <3>;
			xlnx,csi-vc-off-3 = <4>;
			xlnx,csi-vc-off-4 = <5>;
			xlnx,csi-lanes = <2>;
			xlnx,csi-vc-off-5 = <6>;
			xlnx,is-hierarchy;
			xlnx,axis-fifo-depth = <512>;
			xlnx,csi-vc-off-6 = <7>;
			clocks = <&misc_clk_1>, <&misc_clk_4>, <&misc_clk_4>, <&misc_clk_1>, <&misc_clk_0>, <&misc_clk_1>;
			xlnx,axis-fifo-dcnt-width = <9>;
			xlnx,mipi-slv-int = <0>;
			xlnx,csi-vc-off-7 = <8>;
			xlnx,csi-vc-off-8 = <9>;
			xlnx,axis-tdest-width = <4>;
			xlnx,phy-mode = "DPHY";
			xlnx,csi-vc-off-9 = <10>;
			xlnx,edk-iptype = "PERIPHERAL";
			xlnx,cmn-pxl-format = "RAW10";
			xlnx,csi-opt2-crc = <1>;
			clock-names = "core_clk" , "dl0_rxbyteclkhs" , "dl1_rxbyteclkhs" , "m_axis_aclk" , "s_axi_aclk" , "video_aclk";
			xlnx,hp-io-bank-selection = <66>;
			xlnx,csi-opt3-fixedlanes = <1>;
			xlnx,csi-en-vc-support = <1>;
			xlnx,hs-line-rate = <912>;
			xlnx,csi-fixed-vc = <0>;
			xlnx,csi-inv-shutdown = <1>;
			xlnx,axis-tdata-width = <64>;
			xlnx,header-data-width = <32>;
		};
		capture_pipeline_raspi_v_proc_ss_0_hsc: capture_pipeline_raspi_v_proc_ss_0_hsc@0 {
			xlnx,scale-mode = <2>;
			compatible = "xlnx,v-hscaler-1.1";
			xlnx,phase-shift = <6>;
			xlnx,enable-csc = <1>;
			xlnx,max-rows = <1080>;
			xlnx,use-uram = <0>;
			xlnx,ip-name = "v_hscaler";
			xlnx,is-hierarchy;
			reg = <0x0 0x00000000 0x0 0x10000>;
			clocks = <&misc_clk_1>;
			xlnx,s-axi-ctrl-addr-width = <16>;
			xlnx,samples-per-clock = <1>;
			xlnx,max-data-width = <8>;
			xlnx,enable-420 = <1>;
			xlnx,edk-iptype = "PERIPHERAL";
			xlnx,enable-422 = <1>;
			xlnx,max-cols = <1920>;
			status = "okay";
			clock-names = "ap_clk";
			xlnx,num-video-components = <3>;
			xlnx,taps = <6>;
			xlnx,s-axi-ctrl-data-width = <32>;
			xlnx,name = "capture_pipeline_raspi_v_proc_ss_0_hsc";
		};
		capture_pipeline_raspi_v_proc_ss_0_reset_sel_axis: capture_pipeline_raspi_v_proc_ss_0_reset_sel_axis@10000 {
			xlnx,gpio-board-interface = "Custom";
			compatible = "xlnx,axi-gpio-2.0" , "xlnx,xps-gpio-1.00.a";
			xlnx,all-outputs = <0>;
			#gpio-cells = <2>;
			xlnx,gpio-width = <2>;
			xlnx,dout-default = <0x0>;
			xlnx,is-dual = <0>;
			xlnx,ip-name = "axi_gpio";
			xlnx,is-hierarchy;
			xlnx,tri-default-2 = <0xffffffff>;
			reg = <0x0 0x00010000 0x0 0x10000>;
			xlnx,all-inputs-2 = <0>;
			clocks = <&misc_clk_1>;
			xlnx,all-outputs-2 = <0>;
			gpio-controller;
			xlnx,interrupt-present = <0>;
			xlnx,gpio2-board-interface = "Custom";
			xlnx,edk-iptype = "PERIPHERAL";
			xlnx,dout-default-2 = <0x0>;
			status = "okay";
			xlnx,gpio2-width = <32>;
			clock-names = "s_axi_aclk";
			xlnx,tri-default = <0xffffffff>;
			xlnx,name = "capture_pipeline_raspi_v_proc_ss_0_reset_sel_axis";
			xlnx,all-inputs = <0>;
		};
		capture_pipeline_raspi_v_proc_ss_0_vsc: capture_pipeline_raspi_v_proc_ss_0_vsc@20000 {
			xlnx,scale-mode = <2>;
			compatible = "xlnx,v-vscaler-1.1";
			xlnx,phase-shift = <6>;
			xlnx,max-rows = <1080>;
			xlnx,use-uram = <0>;
			xlnx,ip-name = "v_vscaler";
			xlnx,is-hierarchy;
			reg = <0x0 0x00020000 0x0 0x10000>;
			clocks = <&misc_clk_1>;
			xlnx,s-axi-ctrl-addr-width = <12>;
			xlnx,samples-per-clock = <1>;
			xlnx,enable-420 = <1>;
			xlnx,max-data-width = <8>;
			xlnx,edk-iptype = "PERIPHERAL";
			xlnx,max-cols = <1920>;
			status = "okay";
			clock-names = "ap_clk";
			xlnx,num-video-components = <3>;
			xlnx,taps = <6>;
			xlnx,s-axi-ctrl-data-width = <32>;
			xlnx,name = "capture_pipeline_raspi_v_proc_ss_0_vsc";
		};
		vcap_capture_pipeline_isp_v_proc_ss_0 {
			compatible = "xlnx,video";
			dmas = <&capture_pipeline_isp_v_frmbuf_wr_0 0>;
			dma-names = "port0";
			vcap_portscapture_pipeline_isp_v_proc_ss_0: ports {
				#address-cells = <1>;
				#size-cells = <0>;
				vcap_portcapture_pipeline_isp_v_proc_ss_0: port@0 {
					direction = "input";
					reg = <0>;
					capture_pipeline_isp_v_frmbuf_wr_0capture_pipeline_isp_v_proc_ss_0: endpoint {
						remote-endpoint = <&sca_outcapture_pipeline_isp_v_proc_ss_0>;
					};
				};
			};
		};
		vcap_capture_pipeline_raspi_v_proc_ss_0 {
			compatible = "xlnx,video";
			dmas = <&capture_pipeline_raspi_v_frmbuf_wr_0 0>;
			dma-names = "port0";
			vcap_portscapture_pipeline_raspi_v_proc_ss_0: ports {
				#address-cells = <1>;
				#size-cells = <0>;
				vcap_portcapture_pipeline_raspi_v_proc_ss_0: port@0 {
					direction = "input";
					reg = <0>;
					capture_pipeline_raspi_v_frmbuf_wr_0capture_pipeline_raspi_v_proc_ss_0: endpoint {
						remote-endpoint = <&sca_outcapture_pipeline_raspi_v_proc_ss_0>;
					};
				};
			};
		};
	};
};
